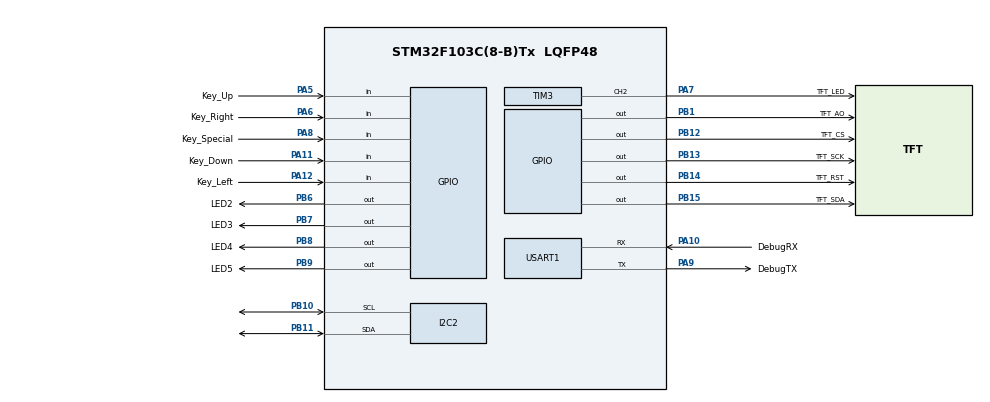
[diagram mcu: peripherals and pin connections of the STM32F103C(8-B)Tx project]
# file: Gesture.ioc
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I2C2.I2C_Mode=I2C_Fast
Mcu.Family=STM32F1
Mcu.Name=STM32F103C(8-B)Tx
Mcu.Package=LQFP48
NVIC.PriorityGroup=NVIC_PRIORITYGROUP_4
PA10.GPIO_Label=DebugRX
PA10.Mode=Asynchronous
PA10.Signal=USART1_RX
PA11.GPIO_Label=Key_Down
PA11.GPIO_PuPd=GPIO_PULLDOWN
PA11.Signal=GPIO_Input
PA12.GPIO_Label=Key_Left
PA12.GPIO_PuPd=GPIO_PULLDOWN
PA12.Signal=GPIO_Input
PA13.Mode=Serial_Wire
PA13.Signal=SYS_JTMS-SWDIO
PA14.Mode=Serial_Wire
PA14.Signal=SYS_JTCK-SWCLK
PA5.GPIO_Label=Key_Up
PA5.GPIO_PuPd=GPIO_PULLDOWN
PA5.Signal=GPIO_Input
PA6.GPIO_Label=Key_Right
PA6.GPIO_PuPd=GPIO_PULLDOWN
PA6.Signal=GPIO_Input
PA7.GPIO_Label=TFT_LED
PA7.Signal=S_TIM3_CH2
PA8.GPIO_Label=Key_Special
PA8.GPIO_PuPd=GPIO_PULLDOWN
PA8.Signal=GPIO_Input
PA9.GPIO_Label=DebugTX
PA9.Mode=Asynchronous
PA9.Signal=USART1_TX
PB1.GPIO_Label=TFT_AO
PB1.GPIO_Speed=GPIO_SPEED_FREQ_HIGH
PB1.Signal=GPIO_Output
PB10.Mode=I2C
PB10.Signal=I2C2_SCL
PB11.Mode=I2C
PB11.Signal=I2C2_SDA
PB12.GPIO_Label=TFT_CS
PB12.GPIO_Speed=GPIO_SPEED_FREQ_HIGH
PB12.Signal=GPIO_Output
PB13.GPIO_Label=TFT_SCK
PB13.GPIO_Speed=GPIO_SPEED_FREQ_HIGH
PB13.Signal=GPIO_Output
PB14.GPIO_Label=TFT_RST
PB14.GPIO_Speed=GPIO_SPEED_FREQ_HIGH
PB14.Signal=GPIO_Output
PB15.GPIO_Label=TFT_SDA
PB15.GPIO_Speed=GPIO_SPEED_FREQ_HIGH
PB15.Signal=GPIO_Output
PB6.GPIO_Label=LED2
PB6.GPIO_Speed=GPIO_SPEED_FREQ_HIGH
PB6.PinState=GPIO_PIN_SET
PB6.Signal=GPIO_Output
PB7.GPIO_Label=LED3
PB7.GPIO_Speed=GPIO_SPEED_FREQ_HIGH
PB7.PinState=GPIO_PIN_SET
PB7.Signal=GPIO_Output
PB8.GPIO_Label=LED4
PB8.GPIO_Speed=GPIO_SPEED_FREQ_HIGH
PB8.PinState=GPIO_PIN_SET
PB8.Signal=GPIO_Output
PB9.GPIO_Label=LED5
PB9.GPIO_Speed=GPIO_SPEED_FREQ_HIGH
PB9.PinState=GPIO_PIN_SET
PB9.Signal=GPIO_Output
PD0-OSC_IN.Mode=HSE-External-Oscillator
PD0-OSC_IN.Signal=RCC_OSC_IN
PD1-OSC_OUT.Mode=HSE-External-Oscillator
PD1-OSC_OUT.Signal=RCC_OSC_OUT
ProjectManager.HeapSize=0x200
ProjectManager.StackSize=0x400
ProjectManager.TargetToolchain=MDK-ARM V5
RCC.AHBFreq_Value=72000000
RCC.APB1CLKDivider=RCC_HCLK_DIV2
RCC.APB1Freq_Value=36000000
RCC.APB1TimFreq_Value=72000000
RCC.APB2Freq_Value=72000000
RCC.APB2TimFreq_Value=72000000
RCC.HCLKFreq_Value=72000000
RCC.HSE_VALUE=12000000
RCC.PLLMUL=RCC_PLL_MUL6
RCC.PLLSourceVirtual=RCC_PLLSOURCE_HSE
RCC.PREFETCH_ENABLE=1
RCC.SYSCLKFreq_VALUE=72000000
RCC.SYSCLKSource=RCC_SYSCLKSOURCE_PLLCLK
RCC.USBFreq_Value=72000000
SH.S_TIM3_CH2.0=TIM3_CH2,PWM Generation2 CH2
TIM3.Channel-PWM\ Generation2\ CH2=TIM_CHANNEL_2
TIM3.Period=11
TIM3.Prescaler=72-1
TIM3.Pulse-PWM\ Generation2\ CH2=11
USART1.VirtualMode=VM_ASYNC
VP_CRC_VS_CRC.Mode=CRC_Activate
VP_TIM3_VS_ClockSourceINT.Mode=Internal
board=custom

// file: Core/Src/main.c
/* USER CODE BEGIN Header */
/**
  ******************************************************************************
  * @file           : main.c
  * @brief          : Main program body
  ******************************************************************************
  ** This notice applies to any and all portions of this file
  * that are not between comment pairs USER CODE BEGIN and
  * USER CODE END. Other portions of this file, whether
  * inserted by the user or by software development tools
  * are owned by their respective copyright owners.
  *
  * COPYRIGHT(c) 2018 STMicroelectronics
  *
  * Redistribution and use in source and binary forms, with or without modification,
  * are permitted provided that the following conditions are met:
  *   1. Redistributions of source code must retain the above copyright notice,
  *      this list of conditions and the following disclaimer.
  *   2. Redistributions in binary form must reproduce the above copyright notice,
  *      this list of conditions and the following disclaimer in the documentation
  *      and/or other materials provided with the distribution.
  *   3. Neither the name of STMicroelectronics nor the names of its contributors
  *      may be used to endorse or promote products derived from this software
  *      without specific prior written permission.
  *
  * THIS SOFTWARE IS PROVIDED BY THE COPYRIGHT HOLDERS AND CONTRIBUTORS "AS IS"
  * AND ANY EXPRESS OR IMPLIED WARRANTIES, INCLUDING, BUT NOT LIMITED TO, THE
  * IMPLIED WARRANTIES OF MERCHANTABILITY AND FITNESS FOR A PARTICULAR PURPOSE ARE
  * DISCLAIMED. IN NO EVENT SHALL THE COPYRIGHT HOLDER OR CONTRIBUTORS BE LIABLE
  * FOR ANY DIRECT, INDIRECT, INCIDENTAL, SPECIAL, EXEMPLARY, OR CONSEQUENTIAL
  * DAMAGES (INCLUDING, BUT NOT LIMITED TO, PROCUREMENT OF SUBSTITUTE GOODS OR
  * SERVICES; LOSS OF USE, DATA, OR PROFITS; OR BUSINESS INTERRUPTION) HOWEVER
  * CAUSED AND ON ANY THEORY OF LIABILITY, WHETHER IN CONTRACT, STRICT LIABILITY,
  * OR TORT (INCLUDING NEGLIGENCE OR OTHERWISE) ARISING IN ANY WAY OUT OF THE USE
  * OF THIS SOFTWARE, EVEN IF ADVISED OF THE POSSIBILITY OF SUCH DAMAGE.
  *
  ******************************************************************************
  */
/* USER CODE END Header */

#include "main.h"
#include "crc.h"
#include "i2c.h"
#include "tim.h"
#include "usart.h"
#include "gpio.h"

/* USER CODE BEGIN Includes */
#include "BSP_LCD.h"
/* USER CODE END Includes */

void SystemClock_Config(void);

int main(void)
{

  /* MCU Configuration--------------------------------------------------------*/

  /* Reset of all peripherals, Initializes the Flash interface and the Systick. */
  HAL_Init();

  /* Configure the system clock */
  SystemClock_Config();

  /* Initialize all configured peripherals */
  MX_GPIO_Init();
  MX_I2C2_Init();
  MX_TIM3_Init();
  MX_CRC_Init();
  MX_USART1_UART_Init();
  /* USER CODE BEGIN 2 */
		HAL_TIM_Base_Start(&htim3);
	 HAL_TIM_PWM_Start(&htim3,TIM_CHANNEL_2);

  LCD_Init();
		LCD_Clear(BLACK);
  /* USER CODE END 2 */

  /* Infinite loop */
  while (1)
  {

  }
}

void SystemClock_Config(void)
{
  LL_FLASH_SetLatency(LL_FLASH_LATENCY_2);

   if(LL_FLASH_GetLatency() != LL_FLASH_LATENCY_2)
  {
    Error_Handler();
  }
  LL_RCC_HSE_Enable();

   /* Wait till HSE is ready */
  while(LL_RCC_HSE_IsReady() != 1)
  {

  }
  LL_RCC_PLL_ConfigDomain_SYS(LL_RCC_PLLSOURCE_HSE_DIV_1, LL_RCC_PLL_MUL_6);
  LL_RCC_PLL_Enable();

   /* Wait till PLL is ready */
  while(LL_RCC_PLL_IsReady() != 1)
  {

  }
  LL_RCC_SetAHBPrescaler(LL_RCC_SYSCLK_DIV_1);
  LL_RCC_SetAPB1Prescaler(LL_RCC_APB1_DIV_2);
  LL_RCC_SetAPB2Prescaler(LL_RCC_APB2_DIV_1);
  LL_RCC_SetSysClkSource(LL_RCC_SYS_CLKSOURCE_PLL);

   /* Wait till System clock is ready */
  while(LL_RCC_GetSysClkSource() != LL_RCC_SYS_CLKSOURCE_STATUS_PLL)
  {

  }
  LL_Init1msTick(72000000);
  LL_SYSTICK_SetClkSource(LL_SYSTICK_CLKSOURCE_HCLK);
  LL_SetSystemCoreClock(72000000);
}

void Error_Handler(void)
{
}

/************************ (C) COPYRIGHT STMicroelectronics *****END OF FILE****/
